# AT32M412xx_v2 register map
Vendor: Keil; Series: AT32M412; File version: 1.0
CPU: CM4 r0p1, little endian, no MPU, FPU, 4 interrupt priority bits
Registers are 32-bit, read-write, reset 0x0 unless marked. A register's access mark holds for its fields unless they carry their own. Offsets are from the block's base; [hi:lo] are bit positions; {n}, {i} and the like mark numbered series.

## TMR1 — Advanced timer
Base 0x40010000
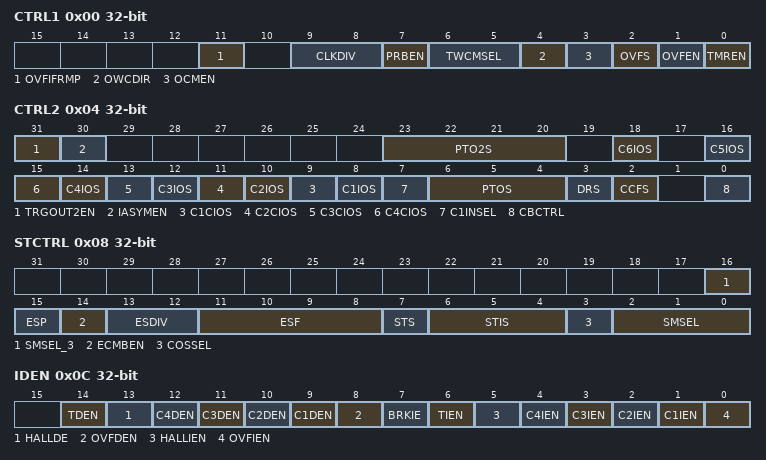
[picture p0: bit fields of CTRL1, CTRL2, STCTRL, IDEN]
0x00 CTRL1 — Control register 1
  [11] OVFIFRMP — OVFIF remap
  [9:8] CLKDIV — Clock divider
  [7] PRBEN — Period buffer enable
  [6:5] TWCMSEL — Two-way count mode selection
  [4] OWCDIR — One-way count direction
  [3] OCMEN — One cycle mode enable
  [2] OVFS — Overflow event source
  [1] OVFEN — Overflow event enable
  [0] TMREN — TMR enable
0x04 CTRL2 — Control register 2
  [31] TRGOUT2EN — TRGOUT2 enable
  [30] IASYMEN — Independently asymmetric PWM mode enable
  [23:20] PTO2S — Primary TMR output2 selection
  [2n+6] C{n}IOS (n=1..6) — Channel {n} idle output state
  [2n+7] C{n}CIOS (n=1..4) — Channel {n} complementary idle output state
  [7] C1INSEL — C1IN selection
  [6:4] PTOS — Primary TMR output selection
  [3] DRS — DMA request source
  [2] CCFS — Channel control bit refresh select
  [0] CBCTRL — Channel buffer control
0x08 STCTRL — Subordinate TMR control register
  [16] SMSEL_3 — Subordinate TMR mode selection bit 3
  [15] ESP — External signal polarity
  [14] ECMBEN — External clock mode B enable
  [13:12] ESDIV — External signal divider
  [11:8] ESF — External signal filter
  [7] STS — Subordinate TMR synchronization
  [6:4] STIS — Subordinate TMR input selection
  [3] COSSEL — Channel output switch selection
  [2:0] SMSEL — Subordinate TMR mode selection
0x0C IDEN — Interrupt/DMA enable register
  [14] TDEN — Trigger DMA request enable
  [13] HALLDE — HALL DMA request enable
  [n+8] C{n}DEN (n=1..4) — Channel {n} DMA request enable
  [8] OVFDEN — Overflow DMA request enable
  [7] BRKIE — Brake interrupt enable
  [6] TIEN — Trigger interrupt enable
  [5] HALLIEN — HALL interrupt enable
  [n] C{n}IEN (n=1..4) — Channel {n} interrupt enable
  [0] OVFIEN — Overflow interrupt enable
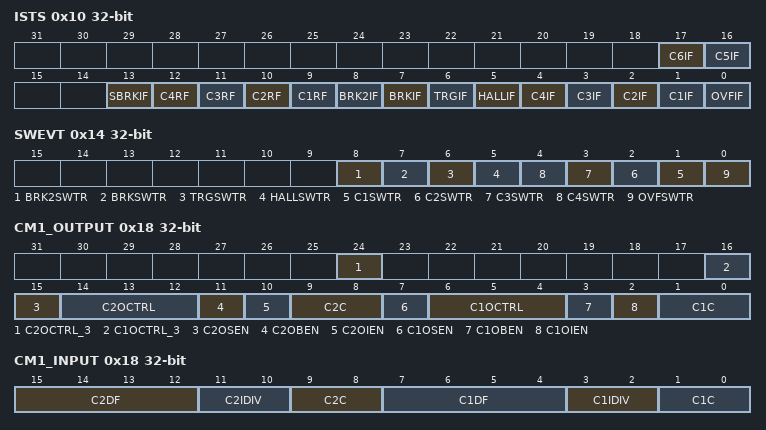
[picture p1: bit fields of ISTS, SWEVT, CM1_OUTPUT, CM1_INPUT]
0x10 ISTS — Interrupt status register
  [17] C6IF — Channel 6 interrupt flag
  [16] C5IF — Channel 5 interrupt flag
  [13] SBRKIF — System brake interrupt flag
  [n+8] C{n}RF (n=1..4) — Channel {n} recapture flag
  [8] BRK2IF — Brake 2 interrupt flag
  [7] BRKIF — Brake interrupt flag
  [6] TRGIF — Trigger interrupt flag
  [5] HALLIF — HALL interrupt flag
  [n] C{n}IF (n=1..4) — Channel {n} interrupt flag
  [0] OVFIF — Overflow interrupt flag
0x14 SWEVT — Software event register
  [8] BRK2SWTR — Brake 2 event triggered by software
  [7] BRKSWTR — Brake event triggered by software
  [6] TRGSWTR — Trigger event triggered by software
  [5] HALLSWTR — HALL event triggered by software
  [n] C{n}SWTR (n=1..4) — Channel {n} event triggered by software
  [0] OVFSWTR — Overflow event triggered by software
0x18 CM1_OUTPUT — Channel output mode register
  [24] C2OCTRL_3 — Channel 2 output control bit 3
  [16] C1OCTRL_3 — Channel 1 output control bit 3
  [15] C2OSEN — Channel 2 output switch enable
  [14:12] C2OCTRL — Channel 2 output control
  [11] C2OBEN — Channel 2 output buffer enable
  [10] C2OIEN — Channel 2 output immediately enable
  [9:8] C2C — Channel 2 configure
  [7] C1OSEN — Channel 1 output switch enable
  [6:4] C1OCTRL — Channel 1 output control
  [3] C1OBEN — Channel 1 output buffer enable
  [2] C1OIEN — Channel 1 output immediately enable
  [1:0] C1C — Channel 1 configure
0x18 CM1_INPUT (alternate view of CM1_OUTPUT) — Channel input mode register 1
  [15:12] C2DF — Channel 2 digital filter
  [11:10] C2IDIV — Channel 2 input divider
  [9:8] C2C — Channel 2 configure
  [7:4] C1DF — Channel 1 digital filter
  [3:2] C1IDIV — Channel 1 input divider
  [1:0] C1C — Channel 1 configure
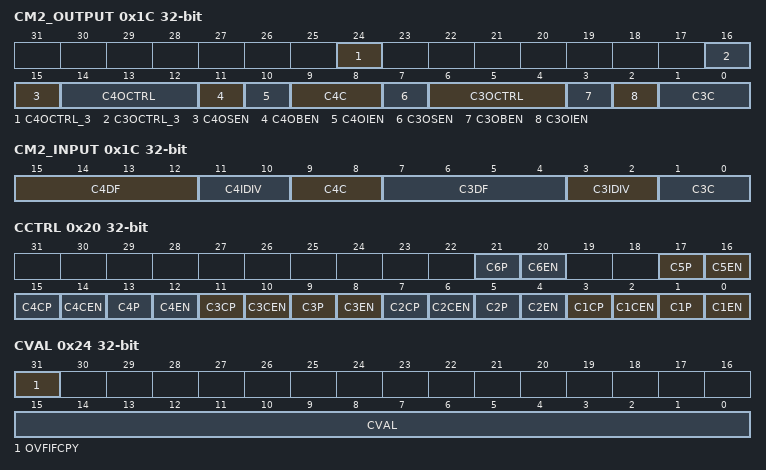
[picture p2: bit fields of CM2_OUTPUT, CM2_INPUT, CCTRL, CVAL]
0x1C CM2_OUTPUT — Channel output mode register 2
  [24] C4OCTRL_3 — Channel 4 output control bit 3
  [16] C3OCTRL_3 — Channel 3 output control bit 3
  [15] C4OSEN — Channel 4 output switch enable
  [14:12] C4OCTRL — Channel 4 output control
  [11] C4OBEN — Channel 4 output buffer enable
  [10] C4OIEN — Channel 4 output immediately enable
  [9:8] C4C — Channel 4 configure
  [7] C3OSEN — Channel 3 output switch enable
  [6:4] C3OCTRL — Channel 3 output control
  [3] C3OBEN — Channel 3 output buffer enable
  [2] C3OIEN — Channel 3 output immediately enable
  [1:0] C3C — Channel 3 configure
0x1C CM2_INPUT (alternate view of CM2_OUTPUT) — Channel input mode register 2
  [15:12] C4DF — Channel 4 digital filter
  [11:10] C4IDIV — Channel 4 input divider
  [9:8] C4C — Channel 4 configure
  [7:4] C3DF — Channel 3 digital filter
  [3:2] C3IDIV — Channel 3 input divider
  [1:0] C3C — Channel 3 configure
0x20 CCTRL — Channel control register
  [4n-3] C{n}P (n=1..6) — Channel {n} Polarity
  [4n-4] C{n}EN (n=1..6) — Channel {n} enable
  [4n-1] C{n}CP (n=1..4) — Channel {n} complementary polarity
  [4n-2] C{n}CEN (n=1..4) — Channel {n} complementary enable
0x24 CVAL — Counter value
  [31] OVFIFCPY — OVFIF copy
  [15:0] CVAL — Counter value
0x28 DIV — Divider value
  [15:0] DIV
0x2C PR — Period value
  [15:0] PR
0x30 RPR — Repetition of period value
  [15:0] RPR
{0x30+4i} C{i}DT (i=1..4) — Channel {i} data register
  [15:0] C{i}DT
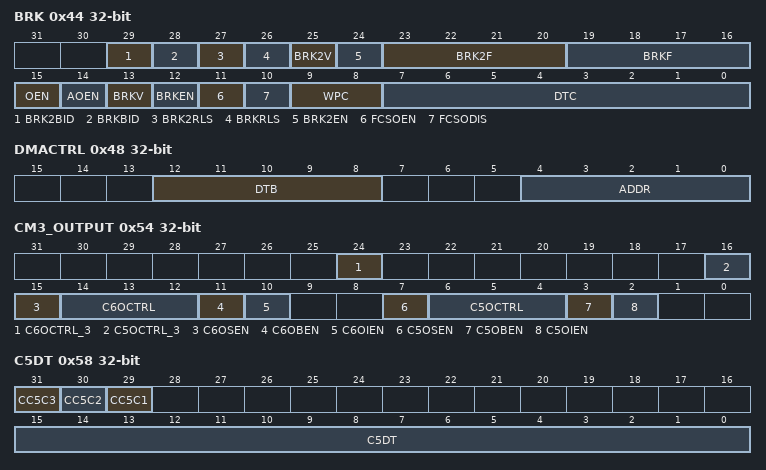
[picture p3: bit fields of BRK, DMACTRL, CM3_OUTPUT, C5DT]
0x44 BRK — Brake register
  [29] BRK2BID — Brake 2 bidirectional
  [28] BRKBID — Brake bidirectional
  [27] BRK2RLS — Brake 2 release
  [26] BRKRLS — Brake release
  [25] BRK2V — Brake 2 input validity
  [24] BRK2EN — Brake 2 enable
  [23:20] BRK2F — Brake 2 input filter
  [19:16] BRKF — Brake input filter
  [15] OEN — Output enable
  [14] AOEN — Automatic output enable
  [13] BRKV — Brake input validity
  [12] BRKEN — Brake enable
  [11] FCSOEN — Frozen channel status when holistic output enable
  [10] FCSODIS — Frozen channel status when holistic output disable
  [9:8] WPC — Write protected configuration
  [7:0] DTC — Dead-time configuration
0x48 DMACTRL — DMA control register
  [12:8] DTB — DMA transfer bytes
  [4:0] ADDR — DMA transfer address offset
0x4C DMADT — DMA data register
  [15:0] DMADT
0x50 OPT1 — Option 1 register
  [0] CORAW_OFF — CORAW_OFF source selection
0x54 CM3_OUTPUT — Channel output mode register
  [24] C6OCTRL_3 — Channel 6 output control bit 3
  [16] C5OCTRL_3 — Channel 5 output control bit 3
  [15] C6OSEN — Channel 6 output switch enable
  [14:12] C6OCTRL — Channel 6 output control
  [11] C6OBEN — Channel 6 output buffer enable
  [10] C6OIEN — Channel 6 output immediately enable
  [7] C5OSEN — Channel 5 output switch enable
  [6:4] C5OCTRL — Channel 5 output control
  [3] C5OBEN — Channel 5 output buffer enable
  [2] C5OIEN — Channel 5 output immediately enable
0x58 C5DT — Channel 5 data register
  [31] CC5C3 — Combine channel 5 and channel 3
  [30] CC5C2 — Combine channel 5 and channel 2
  [29] CC5C1 — Combine channel 5 and channel 1
  [15:0] C5DT — Channel 5 data register
0x5C C6DT — Channel 6 data register
  [15:0] C6DT
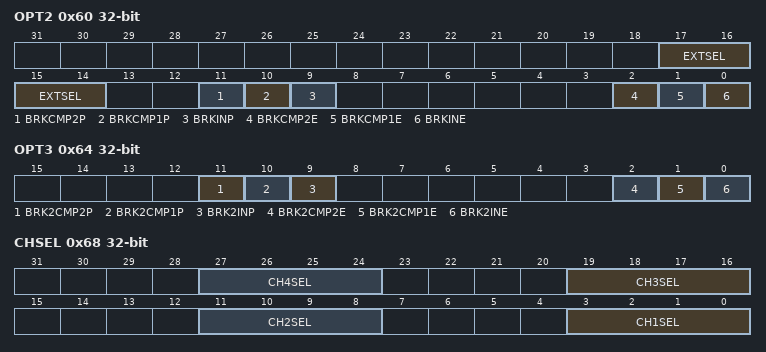
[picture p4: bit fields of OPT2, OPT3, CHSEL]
0x60 OPT2 — Option 2 register
  [17:14] EXTSEL — EXT source selection
  [11] BRKCMP2P — BRK CMP2 input polarity
  [10] BRKCMP1P — BRK CMP1 input polarity
  [9] BRKINP — BRK BKIN input polarity
  [2] BRKCMP2E — BRK CMP2 enable
  [1] BRKCMP1E — BRK CMP1 enable
  [0] BRKINE — BRK BKIN enable
0x64 OPT3 — Option 3 register
  [11] BRK2CMP2P — BRK2 CMP2 input polarity
  [10] BRK2CMP1P — BRK2 CMP1 input polarity
  [9] BRK2INP — BRK2 BKIN input polarity
  [2] BRK2CMP2E — BRK2 CMP2 enable
  [1] BRK2CMP1E — BRK2 CMP1 enable
  [0] BRK2INE — BRK2 BKIN enable
0x68 CHSEL — Channel selection register
  [8n-5:8n-8] CH{n}SEL (n=1..4) — CH{n} input selection
{0x7C+4i} C{i}ADT (i=1..4) — Channel {i} asymmetric data register
  [15:0] C{i}ADT

## Notices in the file
Copyright (C) 2012-2014 ARM Limited. All rights reserved.
Purpose: System Viewer Description (SVD) Example (Schema Version 1.1)
This is a description of a none-existent and incomplete device
for demonstration purposes only.
Redistribution and use in source and binary forms, with or without
modification, are permitted provided that the following conditions are met:
- Redistributions of source code must retain the above copyright
notice, this list of conditions and the following disclaimer.
- Redistributions in binary form must reproduce the above copyright
notice, this list of conditions and the following disclaimer in the
documentation and/or other materials provided with the distribution.
- Neither the name of ARM nor the names of its contributors may be used
to endorse or promote products derived from this software without
specific prior written permission.
THIS SOFTWARE IS PROVIDED BY THE COPYRIGHT HOLDERS AND CONTRIBUTORS "AS IS"
AND ANY EXPRESS OR IMPLIED WARRANTIES, INCLUDING, BUT NOT LIMITED TO, THE
IMPLIED WARRANTIES OF MERCHANTABILITY AND FITNESS FOR A PARTICULAR PURPOSE
ARE DISCLAIMED. IN NO EVENT SHALL COPYRIGHT HOLDERS AND CONTRIBUTORS BE
LIABLE FOR ANY DIRECT, INDIRECT, INCIDENTAL, SPECIAL, EXEMPLARY, OR
CONSEQUENTIAL DAMAGES (INCLUDING, BUT NOT LIMITED TO, PROCUREMENT OF
SUBSTITUTE GOODS OR SERVICES; LOSS OF USE, DATA, OR PROFITS; OR BUSINESS
INTERRUPTION) HOWEVER CAUSED AND ON ANY THEORY OF LIABILITY, WHETHER IN
CONTRACT, STRICT LIABILITY, OR TORT (INCLUDING NEGLIGENCE OR OTHERWISE)
ARISING IN ANY WAY OUT OF THE USE OF THIS SOFTWARE, EVEN IF ADVISED OF THE
POSSIBILITY OF SUCH DAMAGE.
